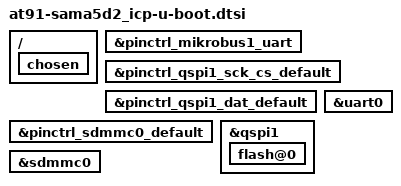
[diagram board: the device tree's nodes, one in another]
// SPDX-License-Identifier: GPL-2.0+ OR MIT
/*
 * at91-sama5d2_icp-for-uboot.dtsi - Device Tree file for SAMA5D2 ICP board
 *			SAMA5D2 Industrial Connectivity Platform
 *
 *  Copyright (c) 2019, Microchip Technology Inc. and its subsidiaries
 *                2019, Eugen Hristev <eugen.hristev@microchip.com>
 */

/ {
	chosen {
		bootph-all;
	};
};

&pinctrl_mikrobus1_uart {
	bootph-all;
};

&pinctrl_qspi1_sck_cs_default {
	bootph-all;
};

&pinctrl_qspi1_dat_default {
	bootph-all;
};

&pinctrl_sdmmc0_default {
	bootph-all;
};

&qspi1 {
	bootph-all;

	flash@0 {
		bootph-all;
	};
};

&sdmmc0 {
	bootph-all;
};

&uart0 { /* mikrobus1 uart */
	bootph-all;
};

